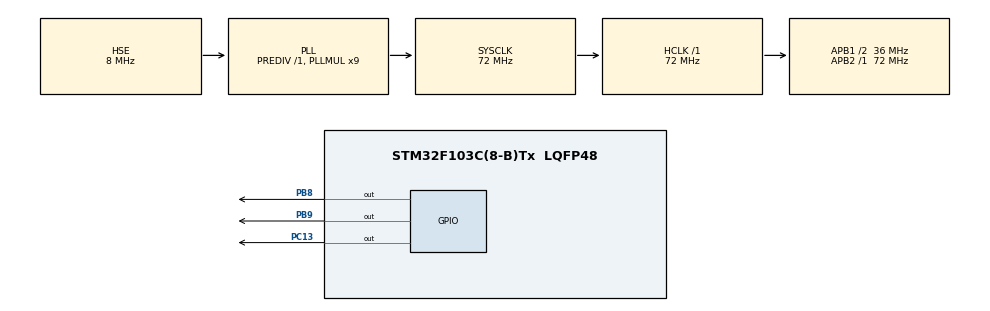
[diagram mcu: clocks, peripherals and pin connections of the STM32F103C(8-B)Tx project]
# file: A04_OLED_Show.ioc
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Mcu.Family=STM32F1
Mcu.Name=STM32F103C(8-B)Tx
Mcu.Package=LQFP48
NVIC.PriorityGroup=NVIC_PRIORITYGROUP_4
NVIC.TIM2_IRQn=true\:0\:0\:false\:false\:true\:true\:true\:true
PA13.Mode=Serial_Wire
PA13.Signal=SYS_JTMS-SWDIO
PA14.Mode=Serial_Wire
PA14.Signal=SYS_JTCK-SWCLK
PB8.GPIO_ModeDefaultOutputPP=GPIO_MODE_OUTPUT_OD
PB8.GPIO_PuPd=GPIO_NOPULL
PB8.Signal=GPIO_Output
PB9.GPIO_ModeDefaultOutputPP=GPIO_MODE_OUTPUT_OD
PB9.GPIO_PuPd=GPIO_NOPULL
PB9.Signal=GPIO_Output
PC13-TAMPER-RTC.Signal=GPIO_Output
PD0-OSC_IN.Mode=HSE-External-Oscillator
PD0-OSC_IN.Signal=RCC_OSC_IN
PD1-OSC_OUT.Mode=HSE-External-Oscillator
PD1-OSC_OUT.Signal=RCC_OSC_OUT
ProjectManager.HeapSize=0x200
ProjectManager.StackSize=0x400
ProjectManager.TargetToolchain=CMake
RCC.AHBFreq_Value=72000000
RCC.APB1CLKDivider=RCC_HCLK_DIV2
RCC.APB1Freq_Value=36000000
RCC.APB1TimFreq_Value=72000000
RCC.APB2Freq_Value=72000000
RCC.APB2TimFreq_Value=72000000
RCC.FLatency=FLASH_LATENCY_2
RCC.HCLKFreq_Value=72000000
RCC.PLLMUL=RCC_PLL_MUL9
RCC.PLLSourceVirtual=RCC_PLLSOURCE_HSE
RCC.SYSCLKFreq_VALUE=72000000
RCC.SYSCLKSource=RCC_SYSCLKSOURCE_PLLCLK
RCC.USBFreq_Value=72000000
TIM2.AutoReloadPreload=TIM_AUTORELOAD_PRELOAD_ENABLE
TIM2.Period=999
TIM2.Prescaler=71
VP_TIM2_VS_ClockSourceINT.Mode=Internal
board=custom

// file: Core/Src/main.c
/* USER CODE BEGIN Header */
/**
  ******************************************************************************
  * @file           : main.c
  * @brief          : Main program body
  ******************************************************************************
  * @attention
  *
  * Copyright (c) 2026 STMicroelectronics.
  * All rights reserved.
  *
  * This software is licensed under terms that can be found in the LICENSE file
  * in the root directory of this software component.
  * If no LICENSE file comes with this software, it is provided AS-IS.
  *
  ******************************************************************************
  */
/* USER CODE END Header */
#include "main.h"
#include "stm32f103xb.h"
#include "tim.h"
#include "gpio.h"

/* USER CODE BEGIN Includes */
#include "LED.h"
#include "OLED.h"
#include <stdio.h>
/* USER CODE END Includes */

/* USER CODE BEGIN PV */
volatile uint8_t progress = 0;  // 进度条，由中断更新
volatile uint8_t show_logo = 0;  // logo显示标志
volatile uint8_t progress_done = 0;  // 进度条是否已完成
/* USER CODE END PV */

void SystemClock_Config(void);

int main(void)
{

  /* USER CODE BEGIN 1 */
  char text[20];

  /* USER CODE END 1 */

  /* MCU Configuration--------------------------------------------------------*/

  /* Reset of all peripherals, Initializes the Flash interface and the Systick. */
  HAL_Init();

  /* Configure the system clock */
  SystemClock_Config();

  /* Initialize all configured peripherals */
  MX_GPIO_Init();
  MX_TIM2_Init();
  /* USER CODE BEGIN 2 */
  LED_OFF();
  OLED_Init();

  OLED_Clear();
  OLED_ShowString(1, 1, "OLED Display");
  OLED_ShowString(2, 1, "STM32F103C8T6");
  OLED_ShowString(3, 1, "Demo Project");
  OLED_Refresh();

  HAL_Delay(2000);  // 显示 2 秒
  HAL_TIM_Base_Start_IT(&htim2);  // 启动定时器中断
  /* USER CODE END 2 */

  /* Infinite loop */
  while (1)
  {

    /* USER CODE BEGIN 3 */
    if (progress_done)
    {
      // 进度条已完成，显示Claude logo
      OLED_Clear();
      OLED_ShowImage(0, 0, 128, 64, claude_logo);
      OLED_Refresh();
    }
    else
    {
      // 清屏
      OLED_Clear();

      // 显示标题
      OLED_ShowString(1, 1, "Progress Bar");

      // 显示进度条
      OLED_ShowProgressBar(2, 1, 100, progress);

      // 显示当前进度百分比
      sprintf(text, "Progress: %3d%%", progress);
      OLED_ShowString(3, 1, text);

      OLED_Refresh();
    }

    HAL_Delay(20);  // 每 20ms 更新一次
  }
  /* USER CODE END 3 */
}

void SystemClock_Config(void)
{
  RCC_OscInitTypeDef RCC_OscInitStruct = {0};
  RCC_ClkInitTypeDef RCC_ClkInitStruct = {0};

  /** Initializes the RCC Oscillators according to the specified parameters
  * in the RCC_OscInitTypeDef structure.
  */
  RCC_OscInitStruct.OscillatorType = RCC_OSCILLATORTYPE_HSE;
  RCC_OscInitStruct.HSEState = RCC_HSE_ON;
  RCC_OscInitStruct.HSEPredivValue = RCC_HSE_PREDIV_DIV1;
  RCC_OscInitStruct.HSIState = RCC_HSI_ON;
  RCC_OscInitStruct.PLL.PLLState = RCC_PLL_ON;
  RCC_OscInitStruct.PLL.PLLSource = RCC_PLLSOURCE_HSE;
  RCC_OscInitStruct.PLL.PLLMUL = RCC_PLL_MUL9;
  if (HAL_RCC_OscConfig(&RCC_OscInitStruct) != HAL_OK)
  {
    Error_Handler();
  }

  /** Initializes the CPU, AHB and APB buses clocks
  */
  RCC_ClkInitStruct.ClockType = RCC_CLOCKTYPE_HCLK|RCC_CLOCKTYPE_SYSCLK
                              |RCC_CLOCKTYPE_PCLK1|RCC_CLOCKTYPE_PCLK2;
  RCC_ClkInitStruct.SYSCLKSource = RCC_SYSCLKSOURCE_PLLCLK;
  RCC_ClkInitStruct.AHBCLKDivider = RCC_SYSCLK_DIV1;
  RCC_ClkInitStruct.APB1CLKDivider = RCC_HCLK_DIV2;
  RCC_ClkInitStruct.APB2CLKDivider = RCC_HCLK_DIV1;

  if (HAL_RCC_ClockConfig(&RCC_ClkInitStruct, FLASH_LATENCY_2) != HAL_OK)
  {
    Error_Handler();
  }
}

/* USER CODE BEGIN 4 */
void	HAL_TIM_PeriodElapsedCallback(TIM_HandleTypeDef *htim)
{
  if (htim->Instance == TIM2)
  {
    static uint32_t count = 0;  // 中断计数器（静态变量，仅在中断内部使用）

    if(count % 5 == 0)  // 5ms 执行一次
    {

    }
    if(count % 20 == 0)  // 20ms 更新一次进度条
    {
      if (!progress_done)  // 进度条未完成才更新
      {
        progress++;
        if (progress >= 100)
        {
          progress = 100;  // 进度条到达100%
          progress_done = 1;  // 设置进度条完成标志
          show_logo = 1;   // 设置显示logo标志
        }
      }
    }
    if(count % 1000 == 0)  // 1s 执行一次
    {
      count = 0;
    }
    count++;
  }
}
/* USER CODE END 4 */

void Error_Handler(void)
{
  __disable_irq();
  while (1)
  {
  }
}
